# F28x7x_xbar_regs register map
Vendor: Texas Instruments
Peripheral module from a debugger description file (folder C2000).
Address unit: 16 bits
Registers are 32-bit, read-only, no defined reset value unless marked. A register's access mark holds for its fields unless they carry their own. Offsets are as the file gives them; lines under a group give offsets from that group; [hi:lo] are bit positions; {n}, {i} and the like mark numbered series; 'fields as' and 'values as' point back to an identical list; <NAME> marks a mode.

## XBAR_REGS — XBAR Registers
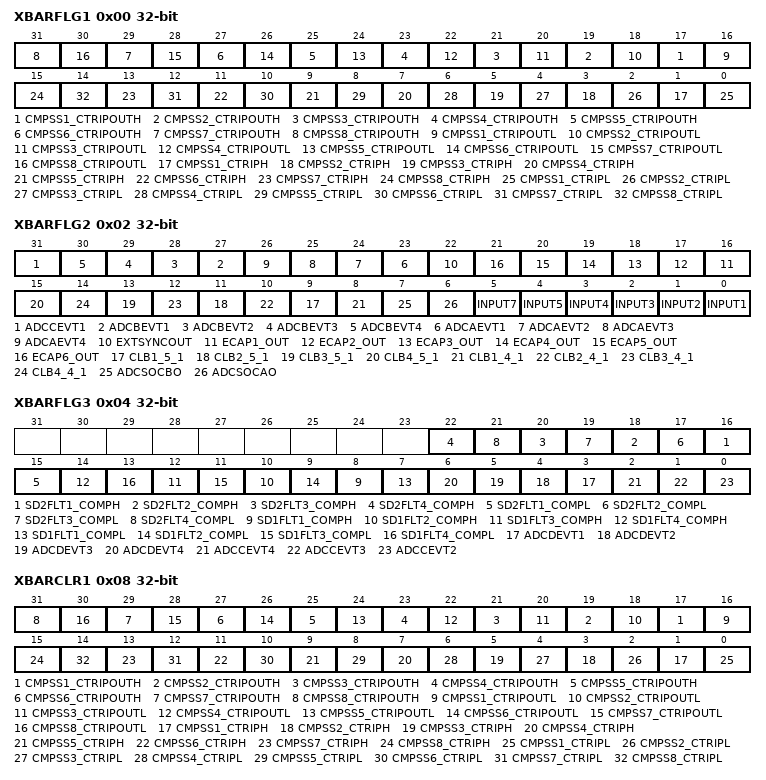
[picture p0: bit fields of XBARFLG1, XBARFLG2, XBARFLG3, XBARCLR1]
0x00 XBARFLG1 — X-Bar Input Flag Register 1
  [2n+15] CMPSS{n}_CTRIPOUTH (n=1..8) — Input Flag for CMPSS{n}.CTRIPOUTH Signal
  [2n+14] CMPSS{n}_CTRIPOUTL (n=1..8) — Input Flag for CMPSS{n}.CTRIPOUTL Signal
  [2n-1] CMPSS{n}_CTRIPH (n=1..8) — Input Flag for CMPSS{n}.CTRIPH Signal
  [2n-2] CMPSS{n}_CTRIPL (n=1..8) — Input Flag for CMPSS{n}.CTRIPL Signal
0x02 XBARFLG2 — X-Bar Input Flag Register 2
  [31] ADCCEVT1 — Input Flag for ADCCEVT1 Signal
  [n+26] ADCBEVT{n} (n=1..4) — Input Flag for ADCBEVT{n} Signal
  [n+22] ADCAEVT{n} (n=1..4) — Input Flag for ADCAEVT{n} Signal
  [22] EXTSYNCOUT — Input Flag for EXTSYNCOUT Signal
  [n+15] ECAP{n}_OUT (n=1..6) — Input Flag for ECAP{n}.OUT Signal
  [2n+7] CLB{n}_5_1 (n=1..4) — Input Flag for CLB{n}_5.1 Signal
  [2n+6] CLB{n}_4_1 (n=1..4) — Input Flag for CLB{n}_4.1 Signal
  [7] ADCSOCBO — Input Flag for ADCSOCBO Signal
  [6] ADCSOCAO — Input Flag for ADCSOCAO Signal
  [5] INPUT7 — Input Flag for INPUT7 Signal
  [n-1] INPUT{n} (n=1..5) — Input Flag for INPUT{n} Signal
0x04 XBARFLG3 — X-Bar Input Flag Register 3
  [2n+14] SD2FLT{n}_COMPH (n=1..4) — Input Flag for SD2FLT{n}.COMPH Signal
  [2n+13] SD2FLT{n}_COMPL (n=1..4) — Input Flag for SD2FLT{n}.COMPL Signal
  [2n+6] SD1FLT{n}_COMPH (n=1..4) — Input Flag for SD1FLT{n}.COMPH Signal
  [2n+5] SD1FLT{n}_COMPL (n=1..4) — Input Flag for SD1FLT{n}.COMPL Signal
  [n+2] ADCDEVT{n} (n=1..4) — Input Flag for ADCDEVT{n} Signal
  [2] ADCCEVT4 — Input Flag for ADCCEVT4 Signal
  [1] ADCCEVT3 — Input Flag for ADCCEVT3 Signal
  [0] ADCCEVT2 — Input Flag for ADCCEVT2 Signal
0x08 XBARCLR1 access not given — X-Bar Input Flag Clear Register 1
  [2n+15] CMPSS{n}_CTRIPOUTH (n=1..8) — Input Flag Clear for CMPSS{n}.CTRIPOUTH Signal (access R=0/W=1)
  [2n+14] CMPSS{n}_CTRIPOUTL (n=1..8) — Input Flag Clear for CMPSS{n}.CTRIPOUTL Signal (access R=0/W=1)
  [2n-1] CMPSS{n}_CTRIPH (n=1..8) — Input Flag Clear for CMPSS{n}.CTRIPH Signal (access R=0/W=1)
  [2n-2] CMPSS{n}_CTRIPL (n=1..8) — Input Flag Clear for CMPSS{n}.CTRIPL Signal (access R=0/W=1)
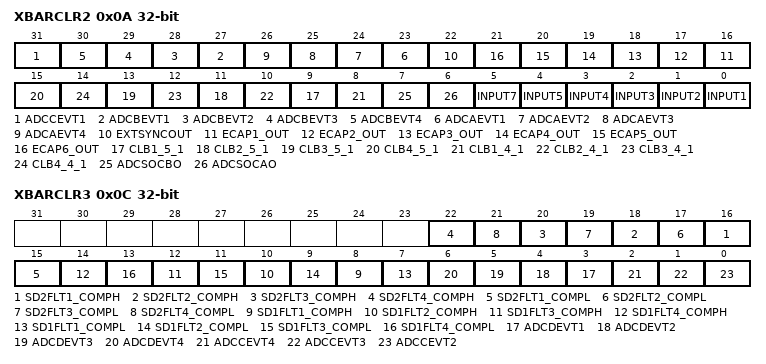
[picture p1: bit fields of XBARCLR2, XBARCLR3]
0x0A XBARCLR2 access not given — X-Bar Input Flag Clear Register 2
  [31] ADCCEVT1 — Input Flag Clear for ADCCEVT1 Signal (access R=0/W=1)
  [n+26] ADCBEVT{n} (n=1..4) — Input Flag Clear for ADCBEVT{n} Signal (access R=0/W=1)
  [n+22] ADCAEVT{n} (n=1..4) — Input Flag Clear for ADCAEVT{n} Signal (access R=0/W=1)
  [22] EXTSYNCOUT — Input Flag Clear for EXTSYNCOUT Signal (access R=0/W=1)
  [n+15] ECAP{n}_OUT (n=1..6) — Input Flag Clear for ECAP{n}.OUT Signal (access R=0/W=1)
  [2n+7] CLB{n}_5_1 (n=1..4) — Input Flag Clear for CLB{n}_5.1 Signal (access R=0/W=1)
  [2n+6] CLB{n}_4_1 (n=1..4) — Input Flag Clear for CLB{n}_4.1 Signal (access R=0/W=1)
  [7] ADCSOCBO — Input Flag Clear for ADCSOCBO Signal (access R=0/W=1)
  [6] ADCSOCAO — Input Flag Clear for ADCSOCAO Signal (access R=0/W=1)
  [5] INPUT7 — Input Flag Clear for INPUT7 Signal (access R=0/W=1)
  [n-1] INPUT{n} (n=1..5) — Input Flag Clear for INPUT{n} Signal (access R=0/W=1)
0x0C XBARCLR3 access not given — X-Bar Input Flag Clear Register 3
  [2n+14] SD2FLT{n}_COMPH (n=1..4) — Input Flag Clear for SD2FLT{n}.COMPH Signal (access R=0/W=1)
  [2n+13] SD2FLT{n}_COMPL (n=1..4) — Input Flag Clear for SD2FLT{n}.COMPL Signal (access R=0/W=1)
  [2n+6] SD1FLT{n}_COMPH (n=1..4) — Input Flag Clear for SD1FLT{n}.COMPH Signal (access R=0/W=1)
  [2n+5] SD1FLT{n}_COMPL (n=1..4) — Input Flag Clear for SD1FLT{n}.COMPL Signal (access R=0/W=1)
  [n+2] ADCDEVT{n} (n=1..4) — Input Flag Clear for ADCDEVT{n} Signal (access R=0/W=1)
  [2] ADCCEVT4 — Input Flag Clear for ADCCEVT4 Signal (access R=0/W=1)
  [1] ADCCEVT3 — Input Flag Clear for ADCCEVT3 Signal (access R=0/W=1)
  [0] ADCCEVT2 — Input Flag Clear for ADCCEVT2 Signal (access R=0/W=1)
